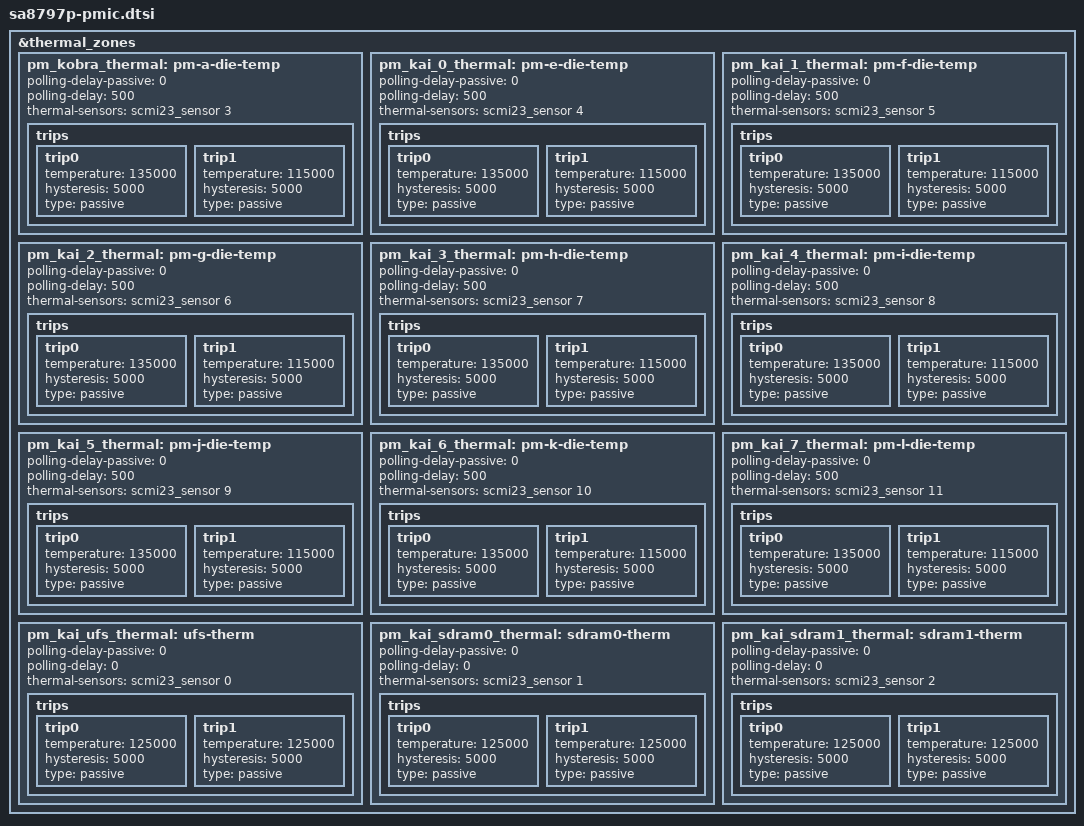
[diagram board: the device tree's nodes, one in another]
// SPDX-License-Identifier: BSD-3-Clause
/*
 * Copyright (c) Qualcomm Technologies, Inc. and/or its subsidiaries.
 */

&thermal_zones {
	pm_kobra_thermal: pm-a-die-temp {
		polling-delay-passive = <0>;
		polling-delay = <500>;
		thermal-sensors = <&scmi23_sensor 3>;

		trips {
			trip0 {
				temperature = <135000>;
				hysteresis = <5000>;
				type = "passive";
			};

			trip1 {
				temperature = <115000>;
				hysteresis = <5000>;
				type = "passive";
			};
		};
	};

	pm_kai_0_thermal: pm-e-die-temp {
		polling-delay-passive = <0>;
		polling-delay = <500>;
		thermal-sensors = <&scmi23_sensor 4>;

		trips {
			trip0 {
				temperature = <135000>;
				hysteresis = <5000>;
				type = "passive";
			};

			trip1 {
				temperature = <115000>;
				hysteresis = <5000>;
				type = "passive";
			};
		};
	};

	pm_kai_1_thermal: pm-f-die-temp {
		polling-delay-passive = <0>;
		polling-delay = <500>;
		thermal-sensors = <&scmi23_sensor 5>;

		trips {
			trip0 {
				temperature = <135000>;
				hysteresis = <5000>;
				type = "passive";
			};

			trip1 {
				temperature = <115000>;
				hysteresis = <5000>;
				type = "passive";
			};
		};
	};

	pm_kai_2_thermal: pm-g-die-temp {
		polling-delay-passive = <0>;
		polling-delay = <500>;
		thermal-sensors = <&scmi23_sensor 6>;

		trips {
			trip0 {
				temperature = <135000>;
				hysteresis = <5000>;
				type = "passive";
			};

			trip1 {
				temperature = <115000>;
				hysteresis = <5000>;
				type = "passive";
			};
		};
	};

	pm_kai_3_thermal: pm-h-die-temp {
		polling-delay-passive = <0>;
		polling-delay = <500>;
		thermal-sensors = <&scmi23_sensor 7>;

		trips {
			trip0 {
				temperature = <135000>;
				hysteresis = <5000>;
				type = "passive";
			};

			trip1 {
				temperature = <115000>;
				hysteresis = <5000>;
				type = "passive";
			};
		};
	};

	pm_kai_4_thermal: pm-i-die-temp {
		polling-delay-passive = <0>;
		polling-delay = <500>;
		thermal-sensors = <&scmi23_sensor 8>;

		trips {
			trip0 {
				temperature = <135000>;
				hysteresis = <5000>;
				type = "passive";
			};

			trip1 {
				temperature = <115000>;
				hysteresis = <5000>;
				type = "passive";
			};
		};
	};

	pm_kai_5_thermal: pm-j-die-temp {
		polling-delay-passive = <0>;
		polling-delay = <500>;
		thermal-sensors = <&scmi23_sensor 9>;

		trips {
			trip0 {
				temperature = <135000>;
				hysteresis = <5000>;
				type = "passive";
			};

			trip1 {
				temperature = <115000>;
				hysteresis = <5000>;
				type = "passive";
			};
		};
	};

	pm_kai_6_thermal: pm-k-die-temp {
		polling-delay-passive = <0>;
		polling-delay = <500>;
		thermal-sensors = <&scmi23_sensor 10>;

		trips {
			trip0 {
				temperature = <135000>;
				hysteresis = <5000>;
				type = "passive";
			};

			trip1 {
				temperature = <115000>;
				hysteresis = <5000>;
				type = "passive";
			};
		};
	};

	pm_kai_7_thermal: pm-l-die-temp {
		polling-delay-passive = <0>;
		polling-delay = <500>;
		thermal-sensors = <&scmi23_sensor 11>;

		trips {
			trip0 {
				temperature = <135000>;
				hysteresis = <5000>;
				type = "passive";
			};

			trip1 {
				temperature = <115000>;
				hysteresis = <5000>;
				type = "passive";
			};
		};
	};

	pm_kai_ufs_thermal: ufs-therm {
		polling-delay-passive = <0>;
		polling-delay = <0>;
		thermal-sensors = <&scmi23_sensor 0>;

		trips {
			trip0 {
				temperature = <125000>;
				hysteresis = <5000>;
				type = "passive";
			};

			trip1 {
				temperature = <125000>;
				hysteresis = <5000>;
				type = "passive";
			};
		};
	};

	pm_kai_sdram0_thermal: sdram0-therm {
		polling-delay-passive = <0>;
		polling-delay = <0>;
		thermal-sensors = <&scmi23_sensor 1>;

		trips {
			trip0 {
				temperature = <125000>;
				hysteresis = <5000>;
				type = "passive";
			};

			trip1 {
				temperature = <125000>;
				hysteresis = <5000>;
				type = "passive";
			};
		};
	};

	pm_kai_sdram1_thermal: sdram1-therm {
		polling-delay-passive = <0>;
		polling-delay = <0>;
		thermal-sensors = <&scmi23_sensor 2>;

		trips {
			trip0 {
				temperature = <125000>;
				hysteresis = <5000>;
				type = "passive";
			};

			trip1 {
				temperature = <125000>;
				hysteresis = <5000>;
				type = "passive";
			};
		};
	};
};
